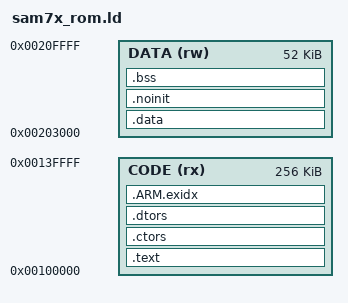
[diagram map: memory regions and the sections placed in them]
OUTPUT_FORMAT("elf32-littlearm", "elf32-littlearm", "elf32-littlearm")
OUTPUT_ARCH(arm)
MEMORY
{
    CODE (rx) : ORIGIN = 0x00100000, LENGTH = 0x00040000
    /* DATA (rw) : ORIGIN = 0x00200000, LENGTH = 0x00010000 */
    DATA (rw) : ORIGIN = 0x00203000, LENGTH = 0x0000D000
}
ENTRY(_start)
SECTIONS
{
    .text :
    {
        *(.init)
        *(.text)
        *(.rodata)

        /* section information for finsh shell */
        . = ALIGN(4);
        __fsymtab_start = .;
        KEEP(*(FSymTab))
        __fsymtab_end = .;
        . = ALIGN(4);
        __vsymtab_start = .;
        KEEP(*(VSymTab))
        __vsymtab_end = .;
        . = ALIGN(4);

        . = ALIGN(4);
        __rt_init_start = .;
        KEEP(*(SORT(.rti_fn*)))
        __rt_init_end = .;
        . = ALIGN(4);

    } > CODE = 0

    . = ALIGN(4);
    .ctors :
    {
        PROVIDE(__ctors_start__ = .);
        KEEP(*(SORT(.ctors.*)))
        KEEP(*(.ctors))
        PROVIDE(__ctors_end__ = .);
    } > CODE

    .dtors :
    {
        PROVIDE(__dtors_start__ = .);
        KEEP(*(SORT(.dtors.*)))
        KEEP(*(.dtors))
        PROVIDE(__dtors_end__ = .);
    } > CODE

    /* .ARM.exidx is sorted, so has to go in its own output section.  */
    __exidx_start = .;
    .ARM.exidx :
    {
        *(.ARM.exidx* .gnu.linkonce.armexidx.*)

        /* This is used by the startup in order to initialize the .data secion */
        _sidata = .;
    } > CODE
    __exidx_end = .;

    /* .data section which is used for initialized data */
    .data : AT (_sidata)
    {
        . = ALIGN(4);
        /* This is used by the startup in order to initialize the .data secion */
        _sdata = . ;

        *(.data)
        *(.data.*)
        *(.gnu.linkonce.d*)

        . = ALIGN(4);
        /* This is used by the startup in order to initialize the .data secion */
        _edata = . ;
    } >DATA
    __data_end = .;

    .noinit :
    {
        *(.bss.noinit)
    } > DATA

    __bss_start = .;
    .bss :
    {
        . = ALIGN(4);
        /* This is used by the startup in order to initialize the .bss secion */
        _sbss = .;

        *(.bss)
        *(COMMON)

        . = ALIGN(4);
        /* This is used by the startup in order to initialize the .bss secion */
        _ebss = . ;
        _estack = .;
    } > DATA
    __bss_end = .;

    _end = .;

}
